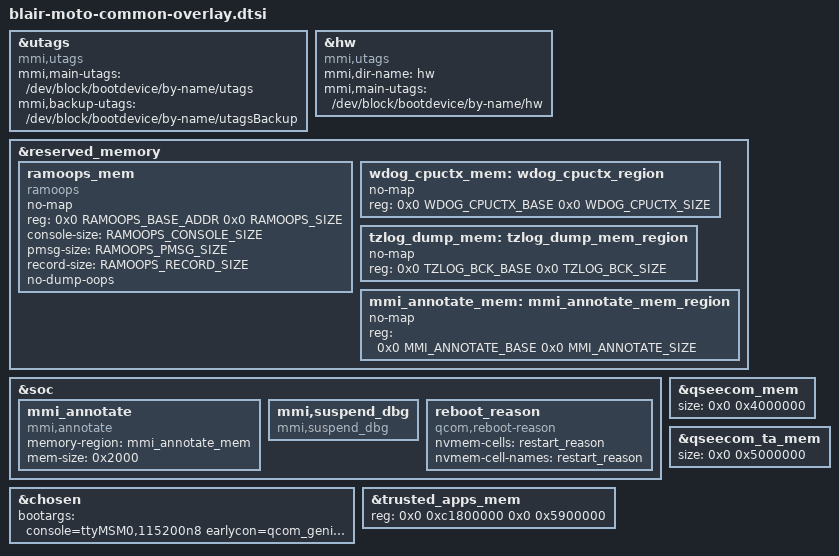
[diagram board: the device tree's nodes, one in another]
/* Copyright (c) 2023, The Linux Foundation. All rights reserved.
 *
 * This program is free software; you can redistribute it and/or modify
 * it under the terms of the GNU General Public License version 2 and
 * only version 2 as published by the Free Software Foundation.
 *
 * This program is distributed in the hope that it will be useful,
 * but WITHOUT ANY WARRANTY; without even the implied warranty of
 * MERCHANTABILITY or FITNESS FOR A PARTICULAR PURPOSE.  See the
 * GNU General Public License for more details.
 */

#include "carrier-channel-ids.dtsi"
#include <dt-bindings/moto/moto-mem-reserve.h>

&utags {
	compatible = "mmi,utags";
	mmi,main-utags = "/dev/block/bootdevice/by-name/utags";
	mmi,backup-utags = "/dev/block/bootdevice/by-name/utagsBackup";
};

&hw {
	compatible = "mmi,utags";
	mmi,dir-name = "hw";
	mmi,main-utags = "/dev/block/bootdevice/by-name/hw";
};

&reserved_memory {
	ramoops_mem {
		compatible = "ramoops";
		no-map;
		reg = <0x0 RAMOOPS_BASE_ADDR 0x0 RAMOOPS_SIZE>;
		console-size = <RAMOOPS_CONSOLE_SIZE>;
		pmsg-size = <RAMOOPS_PMSG_SIZE>;
		record-size = <RAMOOPS_RECORD_SIZE>;
		no-dump-oops;
	};

	wdog_cpuctx_mem: wdog_cpuctx_region {
		no-map;
		reg = <0x0 WDOG_CPUCTX_BASE
				0x0 WDOG_CPUCTX_SIZE>;
	};

	tzlog_dump_mem: tzlog_dump_mem_region {
		no-map;
		reg = <0x0  TZLOG_BCK_BASE
				0x0 TZLOG_BCK_SIZE>;
	};

	mmi_annotate_mem: mmi_annotate_mem_region {
		no-map;
		reg = <0x0  MMI_ANNOTATE_BASE
				0x0 MMI_ANNOTATE_SIZE>;
	};
};

&soc {
	mmi_annotate {
		compatible = "mmi,annotate";
		memory-region = <&mmi_annotate_mem>;
		mem-size = <0x2000>;
	};

	mmi,suspend_dbg {
		compatible = "mmi,suspend_dbg";
	};

	reboot_reason {
		compatible = "qcom,reboot-reason";
		nvmem-cells = <&restart_reason>;
		nvmem-cell-names = "restart_reason";
	};
};

/* bootargs originally copied from blair.dtsi by removing <loglevel=6 log_buf_len=256K> */
/* override bootargs in order to config loglevel and log_buf_len based on build variant */
&chosen {
	bootargs = "console=ttyMSM0,115200n8 earlycon=qcom_geni,0x04C8C000 qcom_geni_serial.con_enabled=1 swiotlb=noforce kernel.panic_on_rcu_stall=1 rcupdate.rcu_expedited=1 fw_devlink.strict=1 service_locator.enable=1 rcu_nocbs=0-7 kpti=off irqaffinity=0-1 cpufreq.default_governor=performance sysctl.kernel.sched_pelt_multiplier=4 no-steal-acc cgroup.memory=nokmem,nosocket printk.console_no_auto_verbose=1 kasan=off loop.max_part=7 can.stats_timer=0  firmware_class.path=/vendor/firmware_mnt/image pcie_ports=compat disable_dma32=on";
};

&trusted_apps_mem {
	reg = <0x0 0xc1800000 0x0 0x5900000>;
};

&qseecom_mem {
	size = <0x0 0x4000000>;
};

&qseecom_ta_mem{
	size = <0x0 0x5000000>;
};
